# ATSAMA5D27WLSOM1 device description
Architecture: CORTEX-A5; Family: SAMA5; Series: SAMA5D2
Registers are 32-bit, read-write, no defined reset value unless marked. A register's access mark holds for its fields unless they carry their own. Offsets are from the block's base; [hi:lo] are bit positions; {n}, {i} and the like mark numbered series; 'fields as' and 'values as' point back to an identical list.

## L2CC — L2 Cache Controller
Instances: L2CC 0x00A00000
0x00 L2CC_IDR ro — Cache ID Register
  [31:0] ID — Cache Controller ID
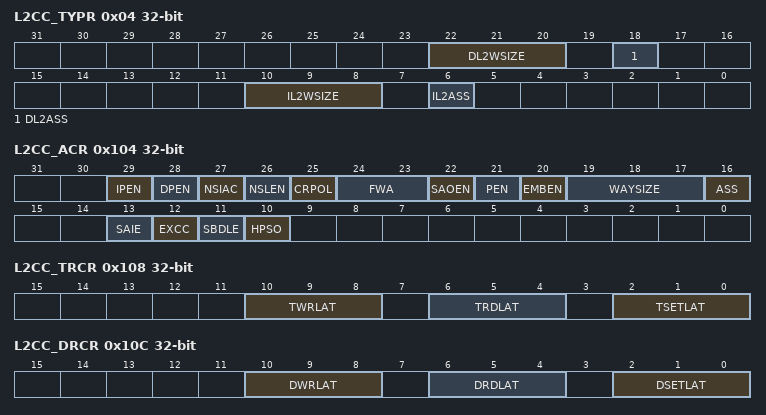
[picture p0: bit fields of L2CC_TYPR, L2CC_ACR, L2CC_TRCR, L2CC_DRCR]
0x04 L2CC_TYPR ro — Cache Type Register
  [22:20] DL2WSIZE — Data L2 Cache Way Size
  [18] DL2ASS — Data L2 Cache Associativity
  [10:8] IL2WSIZE — Instruction L2 Cache Way Size
  [6] IL2ASS — Instruction L2 Cache Associativity
0x100 L2CC_CR — Control Register
  [0] L2CEN — L2 Cache Enable
0x104 L2CC_ACR — Auxiliary Control Register
  [29] IPEN — Instruction Prefetch Enable
  [28] DPEN — Data Prefetch Enable
  [27] NSIAC — Non-Secure Interrupt Access Control
  [26] NSLEN — Non-Secure Lockdown Enable
  [25] CRPOL — Cache Replacement Policy
  [24:23] FWA — Force Write Allocate
  [22] SAOEN — Shared Attribute Override Enable
  [21] PEN — Parity Enable
  [20] EMBEN — Event Monitor Bus Enable
  [19:17] WAYSIZE
    1=_16KB_WAY (16-Kbyte way set associative)
  [16] ASS — Associativity
  [13] SAIE — Shared Attribute Invalidate Enable
  [12] EXCC — Exclusive Cache Configuration
  [11] SBDLE — Store Buffer Device Limitation Enable
  [10] HPSO — High Priority for SO and Dev Reads Enable
0x108 L2CC_TRCR — Tag RAM Control Register
  [10:8] TWRLAT — Write Access Latency
  [6:4] TRDLAT — Read Access Latency
  [2:0] TSETLAT — Setup Latency
0x10C L2CC_DRCR — Data RAM Control Register
  [10:8] DWRLAT — Write Access Latency
  [6:4] DRDLAT — Read Access Latency
  [2:0] DSETLAT — Setup Latency
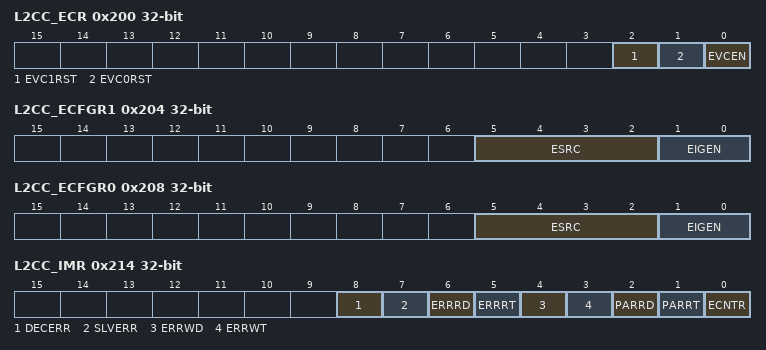
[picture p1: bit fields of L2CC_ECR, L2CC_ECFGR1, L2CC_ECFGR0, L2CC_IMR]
0x200 L2CC_ECR — Event Counter Control Register
  [2] EVC1RST — Event Counter 1 Reset
  [1] EVC0RST — Event Counter 0 Reset
  [0] EVCEN — Event Counter Enable
0x204 L2CC_ECFGR1 — Event Counter 1 Configuration Register
  [5:2] ESRC — Event Counter Source
    0=CNT_DIS (Counter Disabled); 1=SRC_CO (Source is CO); 2=SRC_DRHIT (Source is DRHIT); 3=SRC_DRREQ (Source is DRREQ); 4=SRC_DWHIT (Source is DWHIT); 5=SRC_DWREQ (Source is DWREQ); 6=SRC_DWTREQ (Source is DWTREQ); 7=SRC_IRHIT (Source is IRHIT); 8=SRC_IRREQ (Source is IRREQ); 9=SRC_WA (Source is WA); 10=SRC_IPFALLOC (Source is IPFALLOC); 11=SRC_EPFHIT (Source is EPFHIT); 12=SRC_EPFALLOC (Source is EPFALLOC); 13=SRC_SRRCVD (Source is SRRCVD); 14=SRC_SRCONF (Source is SRCONF); 15=SRC_EPFRCVD (Source is EPFRCVD)
  [1:0] EIGEN — Event Counter Interrupt Generation
    0=INT_DIS (Disables (default)); 1=INT_EN_INCR (Enables with Increment condition); 2=INT_EN_OVER (Enables with Overflow condition); 3=INT_GEN_DIS (Disables Interrupt generation)
0x208 L2CC_ECFGR0 — Event Counter 0 Configuration Register
  fields as L2CC_ECFGR1
0x20C L2CC_EVR1 — Event Counter 1 Value Register
  [31:0] VALUE — Event Counter Value
0x210 L2CC_EVR0 — Event Counter 0 Value Register
  [31:0] VALUE — Event Counter Value
0x214 L2CC_IMR — Interrupt Mask Register
  [8] DECERR — DECERR from L3 Memory
  [7] SLVERR — SLVERR from L3 Memory
  [6] ERRRD — Error on L2 Data RAM, Read
  [5] ERRRT — Error on L2 Tag RAM, Read
  [4] ERRWD — Error on L2 Data RAM, Write
  [3] ERRWT — Error on L2 Tag RAM, Write
  [2] PARRD — Parity Error on L2 Data RAM, Read
  [1] PARRT — Parity Error on L2 Tag RAM, Read
  [0] ECNTR — Event Counter 1/0 Overflow Increment
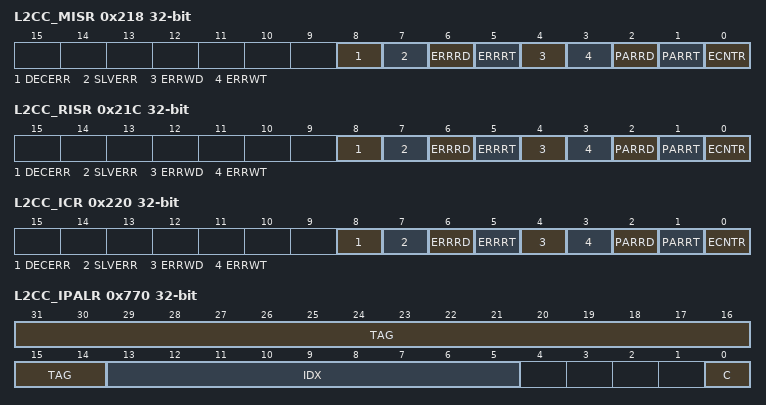
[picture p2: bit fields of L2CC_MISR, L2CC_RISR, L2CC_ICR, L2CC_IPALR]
0x218 L2CC_MISR ro — Masked Interrupt Status Register
  [8] DECERR — DECERR from L3 memory
  [7] SLVERR — SLVERR from L3 memory
  [6] ERRRD — Error on L2 Data RAM, Read
  [5] ERRRT — Error on L2 Tag RAM, Read
  [4] ERRWD — Error on L2 Data RAM, Write
  [3] ERRWT — Error on L2 Tag RAM, Write
  [2] PARRD — Parity Error on L2 Data RAM, Read
  [1] PARRT — Parity Error on L2 Tag RAM, Read
  [0] ECNTR — Event Counter 1/0 Overflow Increment
0x21C L2CC_RISR ro — Raw Interrupt Status Register
  fields as L2CC_MISR
0x220 L2CC_ICR — Interrupt Clear Register
  fields as L2CC_MISR
0x730 L2CC_CSR — Cache Synchronization Register
  [0] C — Cache Synchronization Status
0x770 L2CC_IPALR — Invalidate Physical Address Line Register
  [31:14] TAG — Tag Number
  [13:5] IDX — Index Number
  [0] C — Cache Synchronization Status
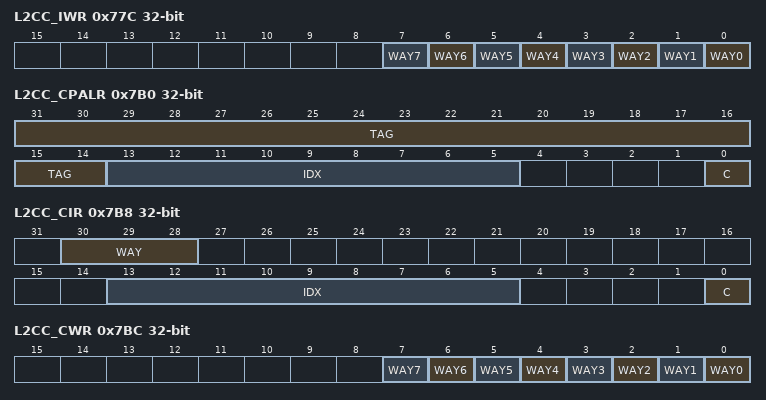
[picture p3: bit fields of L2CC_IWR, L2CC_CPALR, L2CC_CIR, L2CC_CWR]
0x77C L2CC_IWR — Invalidate Way Register
  [n] WAY{n} (n=0..7) — Invalidate Way Number {n}
0x7B0 L2CC_CPALR — Clean Physical Address Line Register
  [31:14] TAG — Tag number
  [13:5] IDX — Index number
  [0] C — Cache Synchronization Status
0x7B8 L2CC_CIR — Clean Index Register
  [30:28] WAY — Way number
  [13:5] IDX — Index number
  [0] C — Cache Synchronization Status
0x7BC L2CC_CWR — Clean Way Register
  [n] WAY{n} (n=0..7) — Clean Way Number {n}
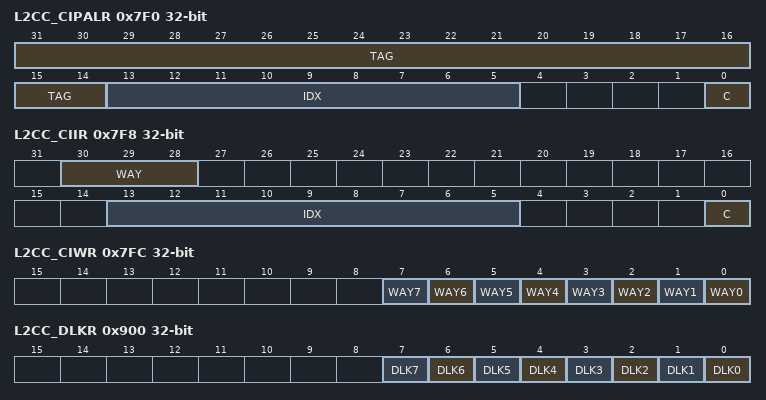
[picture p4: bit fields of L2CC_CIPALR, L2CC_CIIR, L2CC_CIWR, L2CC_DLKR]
0x7F0 L2CC_CIPALR — Clean Invalidate Physical Address Line Register
  fields as L2CC_IPALR
0x7F8 L2CC_CIIR — Clean Invalidate Index Register
  [30:28] WAY — Way Number
  [13:5] IDX — Index Number
  [0] C — Cache Synchronization Status
0x7FC L2CC_CIWR — Clean Invalidate Way Register
  [n] WAY{n} (n=0..7) — Clean Invalidate Way Number {n}
0x900 L2CC_DLKR — Data Lockdown Register
  [n] DLK{n} (n=0..7) — Data Lockdown in Way Number {n}
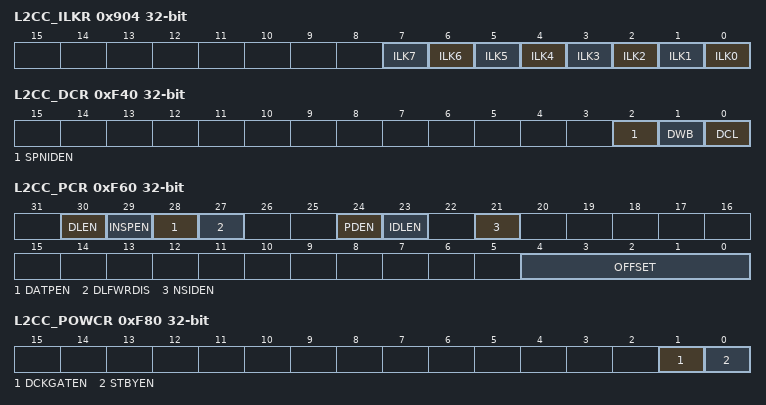
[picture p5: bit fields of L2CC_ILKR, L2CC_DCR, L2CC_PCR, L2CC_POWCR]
0x904 L2CC_ILKR — Instruction Lockdown Register
  [n] ILK{n} (n=0..7) — Instruction Lockdown in Way Number {n}
0xF40 L2CC_DCR — Debug Control Register
  [2] SPNIDEN — SPNIDEN Value
  [1] DWB — Disable Write-back, Force Write-through
  [0] DCL — Disable Cache Linefill
0xF60 L2CC_PCR — Prefetch Control Register
  [30] DLEN — Double Linefill Enable
  [29] INSPEN — Instruction Prefetch Enable
  [28] DATPEN — Data Prefetch Enable
  [27] DLFWRDIS — Double Linefill on WRAP Read Disable
  [24] PDEN — Prefetch Drop Enable
  [23] IDLEN — INCR Double Linefill Enable
  [21] NSIDEN — Not Same ID on Exclusive Sequence Enable
  [4:0] OFFSET — Prefetch Offset
0xF80 L2CC_POWCR — Power Control Register
  [1] DCKGATEN — Dynamic Clock Gating Enable
  [0] STBYEN — Standby Mode Enable
